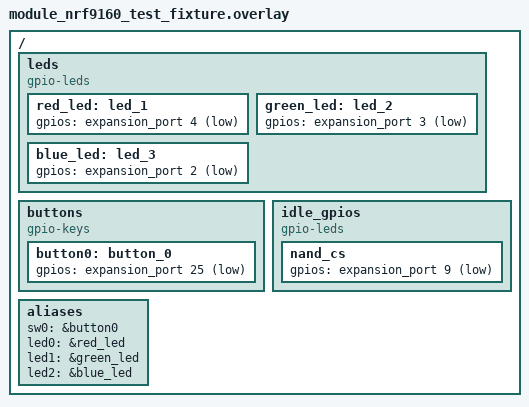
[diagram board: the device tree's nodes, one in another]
/ {
    leds {
        compatible = "gpio-leds";
        red_led: led_1 {
            gpios = <&expansion_port 4 GPIO_ACTIVE_LOW>;
        };
        green_led: led_2 {
            gpios = <&expansion_port 3 GPIO_ACTIVE_LOW>;
        };
        blue_led: led_3 {
            gpios = <&expansion_port 2 GPIO_ACTIVE_LOW>;
        };
    };  

    buttons {
        compatible = "gpio-keys";
        button0: button_0 {
            gpios = <&expansion_port 25 (GPIO_ACTIVE_LOW | GPIO_PULL_UP)>;
        };
    };

    idle_gpios {
        compatible = "gpio-leds";
        nand_cs: nand_cs {
            gpios = <&expansion_port  9 (GPIO_ACTIVE_LOW | GPIO_PULL_UP)>;
        };
    };

    /** @TODO: Add Piezo Beeper */

    aliases {
		sw0 = &button0;
		led0 = &red_led;
		led1 = &green_led;
		led2 = &blue_led;
    };
};
